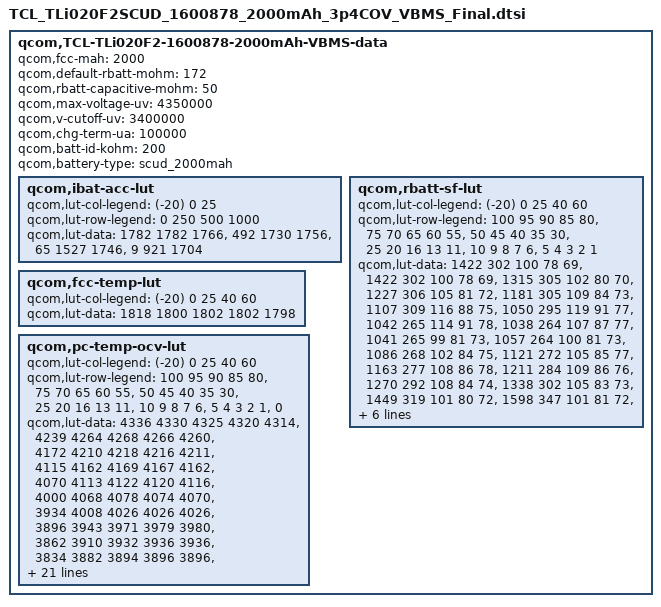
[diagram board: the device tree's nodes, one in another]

 qcom,TCL-TLi020F2-1600878-2000mAh-VBMS-data {
	qcom,fcc-mah = <2000>;
	qcom,default-rbatt-mohm = <172>;
	qcom,rbatt-capacitive-mohm = <50>;
	qcom,max-voltage-uv = <4350000>;
	qcom,v-cutoff-uv = <3400000>;
	qcom,chg-term-ua = <100000>;
	qcom,batt-id-kohm = <200>;
	qcom,battery-type = "scud_2000mah";
	qcom,ibat-acc-lut {
		qcom,lut-col-legend = <(-20) 0 25>;
		qcom,lut-row-legend = <0 250 500 1000>;
		qcom,lut-data = <1782 1782 1766>,
				<492 1730 1756>,
				<65 1527 1746>,
				<9 921 1704>;
	};

	qcom,rbatt-sf-lut {
		qcom,lut-col-legend = <(-20) 0 25 40 60>;
		qcom,lut-row-legend = <100 95 90 85 80>,
				<75 70 65 60 55>,
				<50 45 40 35 30>,
				<25 20 16 13 11>,
				<10 9 8 7 6>,
				<5 4 3 2 1>;
		qcom,lut-data = <1422 302 100 78 69>,
				<1422 302 100 78 69>,
				<1315 305 102 80 70>,
				<1227 306 105 81 72>,
				<1181 305 109 84 73>,
				<1107 309 116 88 75>,
				<1050 295 119 91 77>,
				<1042 265 114 91 78>,
				<1038 264 107 87 77>,
				<1041 265 99 81 73>,
				<1057 264 100 81 73>,
				<1086 268 102 84 75>,
				<1121 272 105 85 77>,
				<1163 277 108 86 78>,
				<1211 284 109 86 76>,
				<1270 292 108 84 74>,
				<1338 302 105 83 73>,
				<1449 319 101 80 72>,
				<1598 347 101 81 72>,
				<1734 366 102 81 73>,
				<1821 383 107 85 76>,
				<1906 401 112 88 78>,
				<1992 419 116 91 81>,
				<2129 438 121 95 84>,
				<2302 450 121 94 84>,
				<2474 460 118 91 83>,
				<2777 470 115 90 82>,
				<3449 475 123 99 87>,
				<4605 501 150 128 119>,
				<39795 2544 299 253 3162>;
	};

	qcom,fcc-temp-lut {
		qcom,lut-col-legend = <(-20) 0 25 40 60>;
		qcom,lut-data = <1818 1800 1802 1802 1798>;
	};

	qcom,pc-temp-ocv-lut {
		qcom,lut-col-legend = <(-20) 0 25 40 60>;
		qcom,lut-row-legend = <100 95 90 85 80>,
				<75 70 65 60 55>,
				<50 45 40 35 30>,
				<25 20 16 13 11>,
				<10 9 8 7 6>,
				<5 4 3 2 1>,
				<0>;
		qcom,lut-data = <4336 4330 4325 4320 4314>,
				<4239 4264 4268 4266 4260>,
				<4172 4210 4218 4216 4211>,
				<4115 4162 4169 4167 4162>,
				<4070 4113 4122 4120 4116>,
				<4000 4068 4078 4074 4070>,
				<3934 4008 4026 4026 4026>,
				<3896 3943 3971 3979 3980>,
				<3862 3910 3932 3936 3936>,
				<3834 3882 3894 3896 3896>,
				<3814 3854 3864 3866 3866>,
				<3798 3831 3840 3841 3841>,
				<3784 3810 3820 3819 3818>,
				<3770 3791 3801 3799 3796>,
				<3755 3774 3782 3778 3770>,
				<3740 3754 3762 3756 3745>,
				<3722 3734 3734 3727 3716>,
				<3703 3718 3709 3701 3689>,
				<3686 3708 3697 3690 3678>,
				<3670 3703 3690 3682 3671>,
				<3660 3698 3688 3680 3668>,
				<3650 3694 3686 3679 3666>,
				<3640 3690 3686 3677 3664>,
				<3622 3686 3684 3676 3662>,
				<3598 3667 3660 3649 3638>,
				<3574 3640 3626 3614 3598>,
				<3539 3611 3594 3578 3556>,
				<3479 3568 3538 3520 3504>,
				<3407 3474 3449 3430 3404>,
				<3278 3370 3337 3315 3286>,
				<3000 3000 3000 3000 3000>;
	};
};
